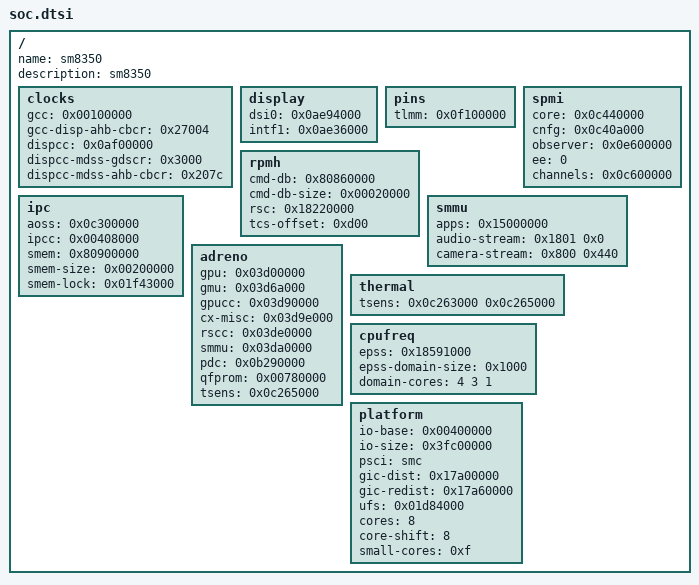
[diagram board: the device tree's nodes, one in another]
/dts-v1/;
// SPDX-License-Identifier: MIT

// sm8350. Started by tools/boards.py new from boot.dts.
// What every board with this SoC shares: where its blocks are (Documentation/porting.md).
/ {
	name = "sm8350";
	description = "sm8350";

	// The clocks the display block's registers need before they can be read: for a "dcs" backlight and
	// the feature "display-scan". The addresses are in the tree; the offsets are not -- they are in Linux's
	// clock drivers for the SoC (gcc-CODENAME.c, dispcc-CODENAME.c).
	clocks {
		gcc = <0x00100000>;             // clock-controller@100000 (qcom,CODENAME-gcc); the only key of this section
		                                // that the part drivers need
		gcc-disp-ahb-cbcr = <0x27004>;		// gcc_disp_ahb_clk: its .halt_reg (gcc-lahaina.c)
		dispcc = <0x0af00000>;          // clock-controller@af00000 (qcom,CODENAME-dispcc)
		dispcc-mdss-gdscr = <0x3000>;		// mdss_core_gdsc: its .gdscr (dispcc-lahaina.c)
		dispcc-mdss-ahb-cbcr = <0x207c>;	// disp_cc_mdss_ahb_clk (dispcc-lahaina.c)
	};

	display {
		dsi0 = <0x0ae94000>;            // the first DSI controller (cell-index 0), reg "dsi_ctrl"
		intf1 = <0x0ae36000>;           // optional, for "display-scan": the same node's reg "mdp_intf_base"
	};

	// The SoC's own pins (TLMM), for the part drivers that drive them: the touch controllers', the speaker
	// amplifier's, the haptic motor's, the cameras'.
	pins {
		tlmm = <0x0f100000>;            // the main SM8350 TLMM (mainline pinctrl@f100000), not LPASS TLMM 0x033c0000
		                                // controller's node (qcom,CODENAME-pinctrl): in Linux's trees its reg; in
		                                // the vendor's, whose reg is the whole 16 MiB block, 0x100000 above it
	};

	// The PMIC arbiter (qcom,spmi-pmic-arb), by its reg-names: for the features "buttons-pmic",
	// "torch-pm8350c" and "camera-sm7325".
	spmi {
		core = <0x0c440000>;            // "core"
		cnfg = <0x0c40a000>;            // "cnfg"
		observer = <0x0e600000>;        // "obsrvr": reads
		ee = <0>;                       // qcom,ee; optional, 0 if left out
		channels = <0x0c600000>;        // "chnls": writes; optional, needed only by the drivers that write to a PMIC
	};

	// RPMh: for the features "ddr-rpmh", "adsp" and "gpu-a660", and for the part drivers that ask it for a
	// supply (the touch controllers', the speaker amplifier's, the cameras', Wi-Fi's).
	rpmh {
		cmd-db = <0x80860000>;          // the reserved-memory node with compatible "qcom,cmd-db": its address
		cmd-db-size = <0x00020000>;     // ... and size
		rsc = <0x18220000>;             // the qcom,rpmh-rsc with qcom,drv-id = <2> (apps_rsc): its reg "drv-2"
		tcs-offset = <0xd00>;           // qcom,tcs-offset of that node
	};

	// The way to the SoC's other processors, for the features "adsp" and "wifi-wcn6750".
	ipc {
		aoss = <0x0c300000>;            // the always-on processor's mailbox: qcom,qmp-mbox (Linux: qcom,aoss-qmp), its reg
		ipcc = <0x00408000>;            // qcom,ipcc, its reg: what the processors ring each other through
		smem = <0x80900000>;            // the memory they share: the memory-region of the qcom,smem node
		smem-size = <0x00200000>;       // ... and its size
		smem-lock = <0x01f43000>;       // the lock on it: hwlocks = <&tcsr_mutex N> of the qcom,smem node, which is
		                                // N x 0x1000 into the qcom,tcsr-mutex block (0x1f40000 + 3 x 0x1000)
	};

	// The SMMU between the SoC's devices and memory, for the part drivers that give a device its addresses
	// (the speakers' audio path, the cameras, Wi-Fi). The GPU's own is in adreno { }.
	smmu {
		apps = <0x15000000>;            // apps_smmu (the vendor's apps-smmu@15000000; Linux's iommu@15000000)
		audio-stream = <0x1801 0x0>;    // for "speaker-aw88261": the stream the audio DSP reads our samples on,
		                                // ID and mask: the iommus of qcom,msm-audio-ion
		camera-stream = <0x800 0x440>;  // for "camera-sm7325": the IFEs' (the iommus of msm_cam_smmu_ife)
	};

	// The Adreno 660 blocks, for the feature "gpu-a660" (qcom,kgsl-3d0 and qcom,gmu).
	adreno {
		gpu = <0x03d00000>;
		gmu = <0x03d6a000>;
		gpucc = <0x03d90000>;
		cx-misc = <0x03d9e000>;
		rscc = <0x03de0000>;
		smmu = <0x03da0000>;
		pdc = <0x0b290000>;
		qfprom = <0x00780000>;
		tsens = <0x0c265000>;
	};
	// Temperature, for a board's thermal { }.
	thermal {
		tsens = <0x0c263000 0x0c265000>; // the TSENS controllers (at most eight), reg "tsens_tm_physical"
	};

	// The cores' frequency hardware, for the feature "cpufreq-epss" and a board's thermal { }: EPSS on the SM8350,
	// SM7325, SC7280 and every chip after them, the OSM's firmware before it (SDM845, SM8150, SM8250, SC7180,
	// SM6350, SM7225). The node is qcom,cpufreq-epss or qcom,cpufreq-hw (the vendor's qcom,cpufreq-hw-epss or
	// qcom,cpufreq-hw); tools/boards.py new --dts reads it, the layout with it.
	cpufreq {
		epss = <0x18591000>;            // the first of its "freq-domainN" regs
		epss-domain-size = <0x1000>;    // their size (at least 0x324 for EPSS, 0x924 for the OSM), and the distance
		                                // from one to the next unless domains says otherwise
		domain-cores = <4 3 1>;         // how many cores each group has, in the cores' order (the cpu@ nodes'
		                                // qcom,freq-domain); one to four groups, together platform { } cores
	};

	// The low-power audio subsystem's blocks on the microphones' path, for the feature "mic-wcd938x". From the
	// SoC's -audio.dtsi (the vendor's). tools/boards.py new finds the addresses and leaves the section commented
	// out, with the SoundWire pins to fill in.
	// lpass {
		// tx-macro = <0x03220000>;     // tx-macro@3220000 (qcom,tx-macro): the codec macro of the capture side
		// va-macro = <0x03370000>;     // va-macro@3370000 (qcom,va-macro)
		// tx-swr = <0x03230000>;       // the SoundWire master under the TX macro (qcom,swr-mstr): its reg
		// tx-swr-hctl = <0x032a90a8>;  // ... and its hardware control register, its qcom,swrm-hctl-reg
		// lpi = <0x033c0000>;          // the subsystem's own pins: lpi_pinctrl@33c0000 (qcom,lpi-pinctrl)
		// lpi-slew = <0x0355a000>;     // ... and that node's qcom,slew-reg
		// swr-tx-pins = <0x...>;       // TO FILL IN: the TX SoundWire master's pins among them, its clock first, then its data
		// swr-tx-slew = <0x...>;       // TO FILL IN: each pin's field in that slew register (the vendor's pinctrl-lpi.c)
	// };

	// What the loader (arch/arm64/boot/) tells the kernel of the machine, for boards with a loader { } section.
	platform {
		io-base = <0x00400000>;	// one window over the SoC's peripherals
		io-size = <0x3fc00000>;	// 0x40000000 - io-base
		psci = "smc";                   // the psci node's method: "smc" or "hvc"
		gic-dist = <0x17a00000>;        // the arm,gic-v3 node's reg: its first entry
		gic-redist = <0x17a60000>;      // ... its second
		ufs = <0x01d84000>;             // optional: the UFS host controller (the ufshc node's reg "ufs_mem"), for the
		                                // loader's and the kernel's own requests to the storage (ufs_native=)
		cores = <8>;                    // the cpu@ nodes
		core-shift = <8>;               // where the core's number is in its reg: 8 for 0x000, 0x100 ..., 0 for 0, 1 ...
		small-cores = <0xf>;            // optional: a bit for each core of the lowest capacity-dmips-mhz
	};
};
